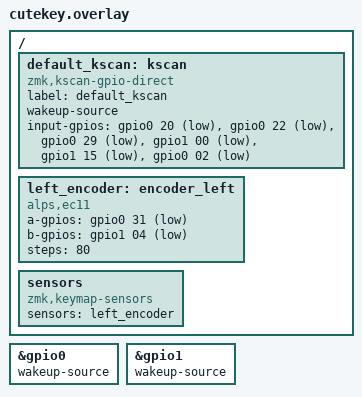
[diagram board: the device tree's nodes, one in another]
/*
 * Copyright (c) 2022 The ZMK Contributors
 *
 * SPDX-License-Identifier: MIT
 */

#include "cutekey-layouts.dtsi"

 / {
    

    default_kscan: kscan {
        compatible = "zmk,kscan-gpio-direct";
        label = "default_kscan";
        wakeup-source;                    /* WAKE-ADD */

        input-gpios
            = <&gpio0 20 (GPIO_ACTIVE_LOW | GPIO_PULL_UP)>,
              <&gpio0 22 (GPIO_ACTIVE_LOW | GPIO_PULL_UP)>,
              <&gpio0 29 (GPIO_ACTIVE_LOW | GPIO_PULL_UP)>,
              <&gpio1 00 (GPIO_ACTIVE_LOW | GPIO_PULL_UP)>,              
              <&gpio1 15 (GPIO_ACTIVE_LOW | GPIO_PULL_UP)>,
              <&gpio0 02 (GPIO_ACTIVE_LOW | GPIO_PULL_UP)>
            ;
    };

    left_encoder: encoder_left {
        compatible = "alps,ec11";
        a-gpios = <&gpio0 31 (GPIO_ACTIVE_LOW | GPIO_PULL_UP)>;
        b-gpios = <&gpio1 04 (GPIO_ACTIVE_LOW | GPIO_PULL_UP)>;
        steps = <80>;
        status = "okay";
    };

    sensors {
        compatible = "zmk,keymap-sensors";
        sensors = <&left_encoder>;
    };

};

/* Enable wake-up on the GPIO controllers that own the keys */
&gpio0 { wakeup-source; };   /* WAKE-ADD */
&gpio1 { wakeup-source; };   /* WAKE-ADD */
